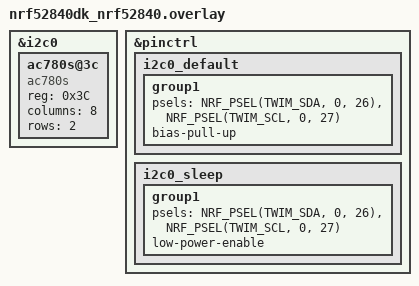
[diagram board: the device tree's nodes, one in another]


&i2c0 {
	status = "okay";
	
    ac780s@3c {
		status = "okay";
		compatible = "ac780s";
		reg = <0x3C>;
		columns = <8>;
		rows = <2>;
	};
};

&pinctrl {
	i2c0_default: i2c0_default{
		group1 {
			psels = <NRF_PSEL(TWIM_SDA, 0, 26)>,
				<NRF_PSEL(TWIM_SCL, 0, 27)>;
			bias-pull-up;
		};
	};

	i2c0_sleep: i2c0_sleep{
		group1 {
			psels = <NRF_PSEL(TWIM_SDA, 0, 26)>,
				<NRF_PSEL(TWIM_SCL, 0, 27)>;
			low-power-enable;
		};
	};

};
